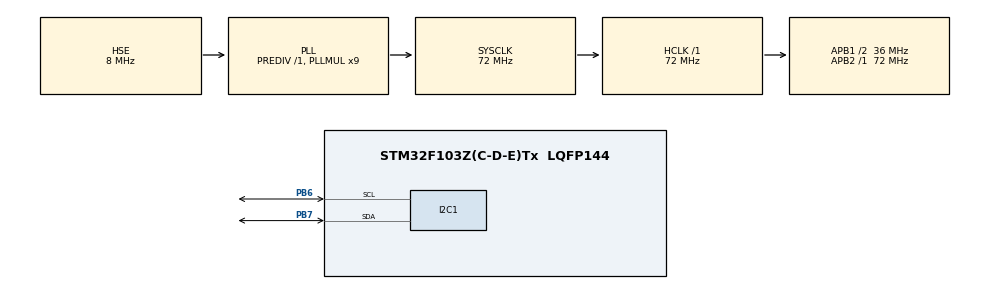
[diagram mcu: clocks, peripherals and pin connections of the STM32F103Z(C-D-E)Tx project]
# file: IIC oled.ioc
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Mcu.Family=STM32F1
RCC.PLLSourceVirtual=RCC_PLLSOURCE_HSE
PC15-OSC32_OUT.Mode=LSE-External-Oscillator
RCC.APB1CLKDivider=RCC_HCLK_DIV2
PC14-OSC32_IN.Signal=RCC_OSC32_IN
RCC.SYSCLKSource=RCC_SYSCLKSOURCE_PLLCLK
ProjectManager.StackSize=0x400
PA13.Signal=SYS_JTMS-SWDIO
ProjectManager.TargetToolchain=MDK-ARM V5.27
RCC.HCLKFreq_Value=72000000
RCC.APB2TimFreq_Value=72000000
PB6.Signal=I2C1_SCL
PB6.Mode=I2C
OSC_IN.Signal=RCC_OSC_IN
RCC.USBFreq_Value=72000000
OSC_OUT.Mode=HSE-External-Oscillator
OSC_OUT.Signal=RCC_OSC_OUT
PC15-OSC32_OUT.Signal=RCC_OSC32_OUT
RCC.AHBFreq_Value=72000000
PB3.Mode=JTAG_5_pins
board=custom
PA15.Mode=JTAG_5_pins
RCC.PLLMUL=RCC_PLL_MUL9
RCC.APB2Freq_Value=72000000
PB4.Mode=JTAG_5_pins
PC14-OSC32_IN.Mode=LSE-External-Oscillator
PA14.Mode=JTAG_5_pins
PB7.Signal=I2C1_SDA
PA13.Mode=JTAG_5_pins
Mcu.Name=STM32F103Z(C-D-E)Tx
PB3.Signal=SYS_JTDO-TRACESWO
RCC.SYSCLKFreq_VALUE=72000000
Mcu.Package=LQFP144
OSC_IN.Mode=HSE-External-Oscillator
PB7.Mode=I2C
PA14.Signal=SYS_JTCK-SWCLK
PA15.Signal=SYS_JTDI
ProjectManager.HeapSize=0x200
NVIC.PriorityGroup=NVIC_PRIORITYGROUP_4
RCC.APB1TimFreq_Value=72000000
RCC.APB1Freq_Value=36000000
PB4.Signal=SYS_NJTRST

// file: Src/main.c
/* USER CODE BEGIN Header */
/**
  ******************************************************************************
  * @file           : main.c
  * @brief          : Main program body
  ******************************************************************************
  * @attention
  *
  * <h2><center>&copy; Copyright (c) 2021 STMicroelectronics.
  * All rights reserved.</center></h2>
  *
  * This software component is licensed by ST under BSD 3-Clause license,
  * the "License"; You may not use this file except in compliance with the
  * License. You may obtain a copy of the License at:
  *                        opensource.org/licenses/BSD-3-Clause
  *
  ******************************************************************************
  */
/* USER CODE END Header */
#include "main.h"
#include "i2c.h"
#include "gpio.h"

/* USER CODE BEGIN Includes */
#include "ssd1306.h"
#include "fonts.h"
/* USER CODE END Includes */

void SystemClock_Config(void);

int main(void)
{

  /* MCU Configuration--------------------------------------------------------*/

  /* Reset of all peripherals, Initializes the Flash interface and the Systick. */
  HAL_Init();

  /* Configure the system clock */
  SystemClock_Config();

  /* Initialize all configured peripherals */
  MX_GPIO_Init();
  MX_I2C1_Init();
  /* USER CODE BEGIN 2 */

  if (ssd1306_Init(&hi2c1) != 0) {
    Error_Handler();
  }
  HAL_Delay(1000);

  ssd1306_Fill(Black);
//  OLED_Clear(&hi2c1);
  ssd1306_UpdateScreen(&hi2c1);

  HAL_Delay(1000);

    // Write data to local screenbuffer
  ssd1306_WriteString(0,0,"ssd1306",Font_11x18,White);

  ssd1306_WriteString(10,18,"Li_Zii",Font_7x10,White);

  ssd1306_ShowNum(20,36,500,3,Font_7x10,White);
  // Draw rectangle on screen
  for (uint8_t i=0; i<28; i++) {
      for (uint8_t j=0; j<64; j++) {
          ssd1306_DrawPixel(100+i,0+j,White);
      }
  }

  ssd1306_ShowCHinese(20,44,0,White);//中

  // Copy all data from local screenbuffer to the screen
  ssd1306_UpdateScreen(&hi2c1);
  /* USER CODE END 2 */

  /* Infinite loop */
  while (1)
  {

  }
}

void SystemClock_Config(void)
{
  RCC_OscInitTypeDef RCC_OscInitStruct = {0};
  RCC_ClkInitTypeDef RCC_ClkInitStruct = {0};

  /** Initializes the RCC Oscillators according to the specified parameters
  * in the RCC_OscInitTypeDef structure.
  */
  RCC_OscInitStruct.OscillatorType = RCC_OSCILLATORTYPE_HSE;
  RCC_OscInitStruct.HSEState = RCC_HSE_ON;
  RCC_OscInitStruct.HSEPredivValue = RCC_HSE_PREDIV_DIV1;
  RCC_OscInitStruct.HSIState = RCC_HSI_ON;
  RCC_OscInitStruct.PLL.PLLState = RCC_PLL_ON;
  RCC_OscInitStruct.PLL.PLLSource = RCC_PLLSOURCE_HSE;
  RCC_OscInitStruct.PLL.PLLMUL = RCC_PLL_MUL9;
  if (HAL_RCC_OscConfig(&RCC_OscInitStruct) != HAL_OK)
  {
    Error_Handler();
  }
  /** Initializes the CPU, AHB and APB buses clocks
  */
  RCC_ClkInitStruct.ClockType = RCC_CLOCKTYPE_HCLK|RCC_CLOCKTYPE_SYSCLK
                              |RCC_CLOCKTYPE_PCLK1|RCC_CLOCKTYPE_PCLK2;
  RCC_ClkInitStruct.SYSCLKSource = RCC_SYSCLKSOURCE_PLLCLK;
  RCC_ClkInitStruct.AHBCLKDivider = RCC_SYSCLK_DIV1;
  RCC_ClkInitStruct.APB1CLKDivider = RCC_HCLK_DIV2;
  RCC_ClkInitStruct.APB2CLKDivider = RCC_HCLK_DIV1;

  if (HAL_RCC_ClockConfig(&RCC_ClkInitStruct, FLASH_LATENCY_2) != HAL_OK)
  {
    Error_Handler();
  }
}

void Error_Handler(void)
{
  __disable_irq();
  while (1)
  {
  }
}

/************************ (C) COPYRIGHT STMicroelectronics *****END OF FILE****/
